# DA14580 register map
Vendor: Dialog; Series: DA14580x; File version: 1.2
CPU: CM0 r1p0, little endian, MPU, FPU, 3 interrupt priority bits
Registers are 16-bit, read-write, reset 0x0 unless marked. A register's access mark holds for its fields unless they carry their own. Offsets are from the block's base; [hi:lo] are bit positions; {n}, {i} and the like mark numbered series.

## kbrd580_nl01 — kbrd580_nl01 registers
Base 0x50001400
0x00 GPIO_IRQ0_IN_SEL_REG — GPIO interrupt selection for GPIO_IRQ0
  [5:0] KBRD_IRQ0_SEL — input selection that can generate a GPIO interrupt 0: no input selected 1: P0[0] is selected 2: P0[1] is selected 3: P0[2] is selected 4: P0[3] is selected 5: P0[4] is selected 6: P0[5] is selected 7: P0[6] is selected 8: P0[7] is selected 9: P1[0] is selected 10: P1[1] is selected 11: P1[2] is selected 12: P1[3] is selected 13: P1[4] is selected 14: P1[5] is selected 15: P2[0] is selected 16: P2[1] is selected 17: P2[2] is selected 18: P2[3] is selected 19: P2[4] is selected 20: P2[5] is selected 21: P2[6] is selected 22: P2[7] is selected 23: P2[8] is selected 24: P2[9] is selected 25: P3[0] is selected 26: P3[1] is selected 27: P3[2] is selected 28: P3[3] is selected 29: P3[4] is selected 30: P3[5] is selected 31: P3[6] is selected 32: P3[7] is selected all others: no input selected
{0x0+2i} GPIO_IRQ{i}_IN_SEL_REG (i=1..4) — GPIO interrupt selection for GPIO_IRQ{i}
  [5:0] KBRD_IRQ{i}_SEL — see KBRD_IRQ0_SEL
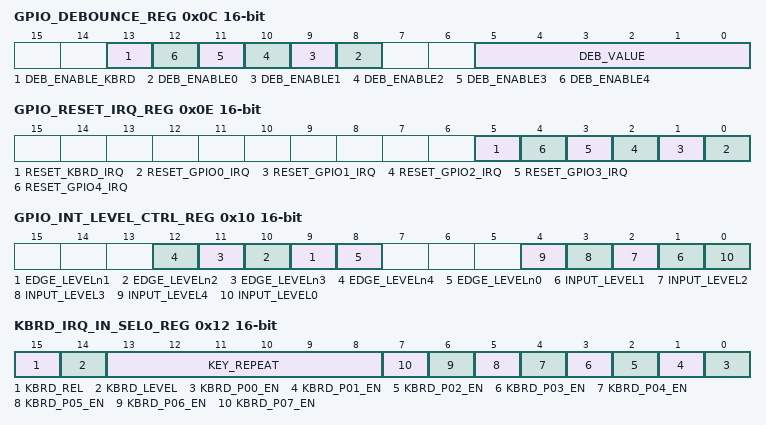
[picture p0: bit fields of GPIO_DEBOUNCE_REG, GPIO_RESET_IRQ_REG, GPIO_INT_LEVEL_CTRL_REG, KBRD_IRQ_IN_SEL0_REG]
0x0C GPIO_DEBOUNCE_REG — debounce counter value for GPIO inputs
  [13] DEB_ENABLE_KBRD — enables the debounce counter for the KBRD interface
  [n+8] DEB_ENABLE{n} (n=0..4) — enables the debounce counter for GPIO IRQ{n}
  [5:0] DEB_VALUE — Keyboard debounce time if enabled. Generate KEYB_INT after specified time. Debounce time: N*1 ms. N =0..63
0x0E GPIO_RESET_IRQ_REG — GPIO interrupt reset register
  [5] RESET_KBRD_IRQ wo — writing a 1 to this bit will reset the KBRD IRQ. Reading returns 0.
  [n] RESET_GPIO{n}_IRQ wo (n=0..4) — writing a 1 to this bit will reset the GPIO{n} IRQ. Reading returns 0.
0x10 GPIO_INT_LEVEL_CTRL_REG — high or low level select for GPIO interrupts
  [n+8] EDGE_LEVELn{n} (n=1..4) — see EDGE_LEVELn0, but for GPIO IRQ{n}
  [8] EDGE_LEVELn0 — 0: do not wait for key release after interrupt was reset for GPIO IRQ0, so a new interrupt can be initiated immediately 1: wait for key release after interrupt was reset for IRQ0
  [n] INPUT_LEVEL{n} (n=1..4) — see INPUT_LEVEL0, but for GPIO IRQ{n}
  [0] INPUT_LEVEL0 — 0 = selected input will generate GPIO IRQ0 if that input is high. 1 = selected input will generate GPIO IRQ0 if that input is low.
0x12 KBRD_IRQ_IN_SEL0_REG — GPIO interrupt selection for KBRD_IRQ for P0
  [15] KBRD_REL — 0 = No interrupt on key release 1 = Interrupt also on key release (also debouncing if enabled)
  [14] KBRD_LEVEL — 0 = enabled input will generate KBRD IRQ if that input is high. 1 = enabled input will generate KBRD IRQ if that input is low.
  [13:8] KEY_REPEAT — While key is pressed, automatically generate repeating KEYB_INT after specified time unequal to 0. Repeat time: N*1 ms. N =1..63, N=0 disables the timer.
  [n] KBRD_P{n:02}_EN (n=0..7) — enable P0[{n}] for the keyboard interrupt
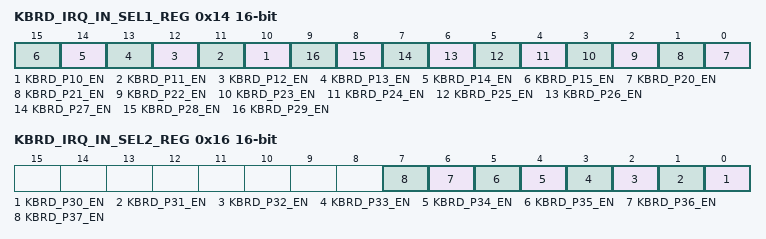
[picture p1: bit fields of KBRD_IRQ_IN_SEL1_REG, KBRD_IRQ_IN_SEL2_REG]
0x14 KBRD_IRQ_IN_SEL1_REG — GPIO interrupt selection for KBRD_IRQ for P1 and P2
  [n] KBRD_P{n}_EN (n=10..15) — enable P1[{n-10}] for the keyboard interrupt
  [n-20] KBRD_P{n}_EN (n=20..29) — enable P2[{n-20}] for the keyboard interrupt
0x16 KBRD_IRQ_IN_SEL2_REG — GPIO interrupt selection for KBRD_IRQ for P3
  [n-30] KBRD_P{n}_EN (n=30..37) — enable P3[{n-30}] for the keyboard interrupt

## quadec580_gr01 — quadec580_gr01 registers
Base 0x50000200
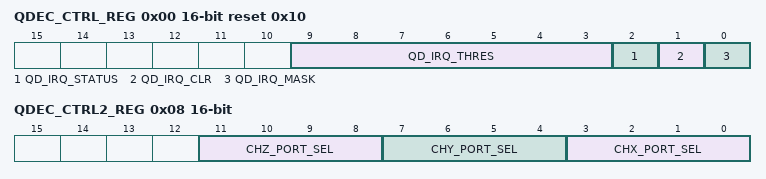
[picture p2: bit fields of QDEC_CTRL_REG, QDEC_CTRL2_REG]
0x00 QDEC_CTRL_REG reset 0x10 — Quad Decoder control register
  [9:3] QD_IRQ_THRES — The number of events on either counter (X or Y) that need to be reached before an interrupt is generated. If 0 is written, then threshold is considered to be 1.
  [2] QD_IRQ_STATUS ro — Interrupt Status. If 1 an interrupt has occured.
  [1] QD_IRQ_CLR — Writing 1 to this bit clears the interrupt. This bit is autocleared
  [0] QD_IRQ_MASK — 0: interrupt is masked 1: interrupt is enabled
0x02 QDEC_XCNT_REG — Counter value of the X Axis
  [15:0] X_counter ro — Contains a signed value of the events. Zero when channel is disabled
0x04 QDEC_YCNT_REG — Counter value of the Y Axis
  [15:0] Y_counter ro — Contains a signed value of the events. Zero when channel is disabled
0x06 QDEC_CLOCKDIV_REG — Clock divider register
  [9:0] clock_divider — Contains the number of the input clock cycles minus one, that are required to generate one logic clock cycle.
0x08 QDEC_CTRL2_REG — Quad Decoder control register
  [11:8] CHZ_PORT_SEL — Defines which GPIOs are mapped on Channel Z 0: none 1: P0[0] -> CHZ_A, P0[1] -> CHZ_B 2: P0[2] -> CHZ_A, P0[3] -> CHZ_B 3: P0[4] -> CHZ_A, P0[5] -> CHZ_B 4: P0[6] -> CHZ_A, P0[7] -> CHZ_B 5: P1[0] -> CHZ_A, P1[1] -> CHZ_B 6: P1[2] -> CHZ_A, P1[3] -> CHZ_B 7: P2[3] -> CHZ_A, P2[4] -> CHZ_B 8: P2[5] -> CHZ_A, P2[6] -> CHZ_B 9: P2[7] -> CHZ_A, P2[8] -> CHZ_B 10: P2[9] -> CHZ_A, P2[0] -> CHZ_B 11..15: None
  [7:4] CHY_PORT_SEL — Defines which GPIOs are mapped on Channel Y 0: none 1: P0[0] -> CHY_A, P0[1] -> CHY_B 2: P0[2] -> CHY_A, P0[3] -> CHY_B 3: P0[4] -> CHY_A, P0[5] -> CHY_B 4: P0[6] -> CHY_A, P0[7] -> CHY_B 5: P1[0] -> CHY_A, P1[1] -> CHY_B 6: P1[2] -> CHY_A, P1[3] -> CHY_B 7: P2[3] -> CHY_A, P2[4] -> CHY_B 8: P2[5] -> CHY_A, P2[6] -> CHY_B 9: P2[7] -> CHY_A, P2[8] -> CHY_B 10: P2[9] -> CHY_A, P2[0] -> CHY_B 11..15: None
  [3:0] CHX_PORT_SEL — Defines which GPIOs are mapped on Channel X 0: none 1: P0[0] -> CHX_A, P0[1] -> CHX_B 2: P0[2] -> CHX_A, P0[3] -> CHX_B 3: P0[4] -> CHX_A, P0[5] -> CHX_B 4: P0[6] -> CHX_A, P0[7] -> CHX_B 5: P1[0] -> CHX_A, P1[1] -> CHX_B 6: P1[2] -> CHX_A, P1[3] -> CHX_B 7: P2[3] -> CHX_A, P2[4] -> CHX_B 8: P2[5] -> CHX_A, P2[6] -> CHX_B 9: P2[7] -> CHX_A, P2[8] -> CHX_B 10: P2[9] -> CHX_A, P2[0] -> CHX_B 11..15: None
0x0A QDEC_ZCNT_REG — Z_counter
  [15:0] Z_counter ro — Contains a signed value of the events. Zero when channel is disabled
